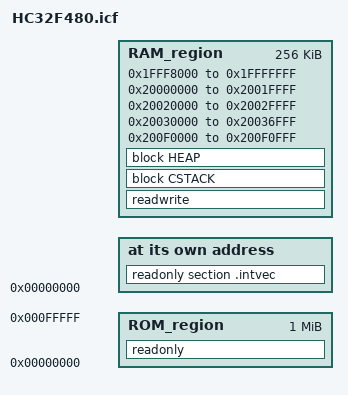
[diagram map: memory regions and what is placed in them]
/*###ICF### Section handled by ICF editor, don't touch! ****/
/*-Editor annotation file-*/
/* IcfEditorFile="$TOOLKIT_DIR$\config\ide\IcfEditor\cortex_v1_0.xml" */
/*-Specials-*/
define symbol __ICFEDIT_intvec_start__ = 0x00000000;
/*-Memory Regions-*/
define symbol __ICFEDIT_region_ROM_start__  = 0x00000000;
define symbol __ICFEDIT_region_ROM_end__    = 0x000FFFFF;
define symbol __ICFEDIT_region_RAM1_start__ = 0x1FFF8000;
define symbol __ICFEDIT_region_RAM1_end__   = 0x1FFFFFFF;
define symbol __ICFEDIT_region_RAM2_start__ = 0x20000000;
define symbol __ICFEDIT_region_RAM2_end__   = 0x2001FFFF;
define symbol __ICFEDIT_region_RAM3_start__ = 0x20020000;
define symbol __ICFEDIT_region_RAM3_end__   = 0x2002FFFF;
define symbol __ICFEDIT_region_RAM4_start__ = 0x20030000;
define symbol __ICFEDIT_region_RAM4_end__   = 0x20036FFF;
define symbol __ICFEDIT_region_RAM5_start__ = 0x200F0000;
define symbol __ICFEDIT_region_RAM5_end__   = 0x200F0FFF;

/*-Sizes-*/
define symbol __ICFEDIT_size_cstack__ = 0x400;
define symbol __ICFEDIT_size_heap__   = 0x400;
/**** End of ICF editor section. ###ICF###*/

define memory mem with size = 4G;
define region ROM_region       = mem:[from __ICFEDIT_region_ROM_start__   to __ICFEDIT_region_ROM_end__];
define region RAM_region       =   mem:[from __ICFEDIT_region_RAM1_start__   to __ICFEDIT_region_RAM1_end__]
                                 | mem:[from __ICFEDIT_region_RAM2_start__   to __ICFEDIT_region_RAM2_end__]
                                 | mem:[from __ICFEDIT_region_RAM3_start__   to __ICFEDIT_region_RAM3_end__]
                                 | mem:[from __ICFEDIT_region_RAM4_start__   to __ICFEDIT_region_RAM4_end__]
                                 | mem:[from __ICFEDIT_region_RAM5_start__   to __ICFEDIT_region_RAM5_end__];

define block CSTACK    with alignment = 8, size = __ICFEDIT_size_cstack__   { };
define block HEAP      with alignment = 8, size = __ICFEDIT_size_heap__     { };

initialize by copy { readwrite };
do not initialize  { section .noinit };

place at address mem:__ICFEDIT_intvec_start__ { readonly section .intvec };

place in ROM_region   { readonly };
place in RAM_region   { readwrite,
                        block CSTACK, block HEAP };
